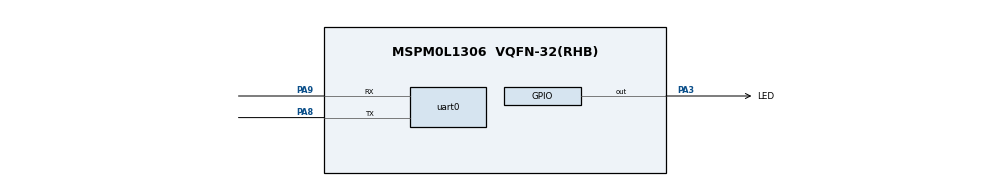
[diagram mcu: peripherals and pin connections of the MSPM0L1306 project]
/**
 * CCS SysConfig source for the MSPM0L1306 core board.
 */
//@cliArgs --device "MSPM0L130X" --package "VQFN-32(RHB)" --part "Default"
//@v2CliArgs --device "MSPM0L1306" --package "VQFN-32(RHB)"
// @cliArgs --board /ti/boards/LP_MSPM0L1306 --rtos nortos

const GPIO = scripting.addModule("/ti/driverlib/GPIO", {}, false);
const led4 = GPIO.addInstance();

led4.$name = "GPIO_LED4";
led4.port = "PORTA";
led4.associatedPins.create(1);
led4.associatedPins[0].$name = "LED";
led4.associatedPins[0].pin.$assign = "PA3";

const UART = scripting.addModule("/ti/driverlib/UART", {}, false);
const uart0 = UART.addInstance();

uart0.$name = "UART_0";
uart0.profile = "CONFIG_PROFILE_1";
uart0.peripheral.$assign = "UART0";
uart0.targetBaudRate = 115200;
uart0.enableInternalLoopback = false;
uart0.enabledInterrupts = ["RX"];
uart0.enableFIFO = false;
uart0.peripheral.txPin.$assign = "PA8";
uart0.peripheral.rxPin.$assign = "PA9";

const SYSCTL = scripting.addModule("/ti/driverlib/SYSCTL");
SYSCTL.clockTreeEn = true;
